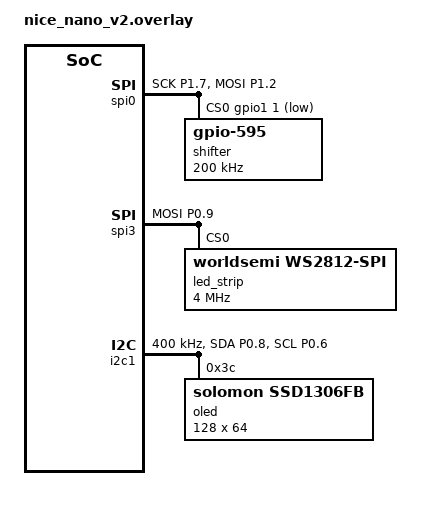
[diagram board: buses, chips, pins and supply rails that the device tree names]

/**
 * Generated by Shield Wizard for ZMK
 * Applies to shield "shifter_test_right" with board "nice_nano_v2" only
 */

//
// ======== spi0 ========
//

// pin control for spi0
// - SCK on P1.07
// - MOSI on P1.02
&pinctrl {
    /* configuration for spi0 device, default state */
    spi0_default: spi0_default {
        group1 {
            psels = <NRF_PSEL(SPIM_SCK, 1, 7)>,
                    <NRF_PSEL(SPIM_MOSI, 1, 2)>;
        };
    };
    /* configuration for spi0 device, sleep state */
    spi0_sleep: spi0_sleep {
        group1 {
            psels = <NRF_PSEL(SPIM_SCK, 1, 7)>,
                    <NRF_PSEL(SPIM_MOSI, 1, 2)>;
            low-power-enable;
        };
    };
};
&spi0 {
  compatible = "nordic,nrf-spim";
  status = "okay";
  pinctrl-0 = <&spi0_default>;
  pinctrl-1 = <&spi0_sleep>;
  pinctrl-names = "default", "sleep";
};

// devices on spi0

// CS pins for devices on spi0
&spi0 {
    cs-gpios = <&gpio1 1 GPIO_ACTIVE_LOW>;
};

&spi0 {
    shifter: 595@0 {
        compatible = "zmk,gpio-595";
        reg = <0>;
        status = "okay";
        gpio-controller;
        spi-max-frequency = <200000>;
        #gpio-cells = <2>;
        ngpios = <16>;
    };
};

//
// ======== spi3 ========
//

// pin control for spi3
// - MOSI on D10
&pinctrl {
    /* configuration for spi3 device, default state */
    spi3_default: spi3_default {
        group1 {
            psels = <NRF_PSEL(SPIM_MOSI, 0, 9)>;
        };
    };
    /* configuration for spi3 device, sleep state */
    spi3_sleep: spi3_sleep {
        group1 {
            psels = <NRF_PSEL(SPIM_MOSI, 0, 9)>;
            low-power-enable;
        };
    };
};
&spi3 {
  compatible = "nordic,nrf-spim";
  status = "okay";
  pinctrl-0 = <&spi3_default>;
  pinctrl-1 = <&spi3_sleep>;
  pinctrl-names = "default", "sleep";
};

// devices on spi3

// CS pins not defined for all devices on spi3, skipping CS pin configuration

&spi3 {
    led_strip: ws2812@0 {
        compatible = "worldsemi,ws2812-spi";
        reg = <0>;
        spi-max-frequency = <4000000>;

        chain-length = <13>;
        spi-one-frame = <0x70>;
        spi-zero-frame = <0x40>;
        color-mapping = <LED_COLOR_ID_GREEN
                         LED_COLOR_ID_RED
                         LED_COLOR_ID_BLUE>;
    };
};
/ {
    chosen {
        zmk,underglow = &led_strip;
    };
};

//
// ======== i2c1 ========
//

// pin control for i2c1
// - SDA on D0
// - SCL on D1
&pinctrl {
    /* configuration for i2c1 device, default state */
    i2c1_default: i2c1_default {
        group1 {
            psels = <NRF_PSEL(TWIM_SDA, 0, 8)>,
                    <NRF_PSEL(TWIM_SCL, 0, 6)>;
        };
    };
    /* configuration for i2c1 device, sleep state */
    i2c1_sleep: i2c1_sleep {
        group1 {
            psels = <NRF_PSEL(TWIM_SDA, 0, 8)>,
                    <NRF_PSEL(TWIM_SCL, 0, 6)>;
            low-power-enable;
        };
    };
};
&i2c1 {
  compatible = "nordic,nrf-twim";
  status = "okay";
  pinctrl-0 = <&i2c1_default>;
  pinctrl-1 = <&i2c1_sleep>;
  pinctrl-names = "default", "sleep";
  clock-frequency = <I2C_BITRATE_FAST>;
};

// devices on i2c1

&i2c1 {
    oled: ssd1306@3c {
        compatible = "solomon,ssd1306fb";
        reg = <0x3c>;
        width = <128>;
        height = <64>;

        segment-offset = <0>;
        page-offset = <0>;
        display-offset = <0>;
        multiplex-ratio = <31>;
        prechargep = <0x22>;
        segment-remap;
        com-invdir;
        com-sequential;
        inversion-on;
    };
};
/ {
    chosen {
        zephyr,display = &oled;
    };
};
